AUTOSAR XML (schema 00047)
package /AUTOSAR/StdTypes
  11 x std cpp implementation data type, all with category=VALUE:
    bool
    float
    double
    int8_t: type-emitter=cstdint
    int16_t: type-emitter=cstdint
    int32_t: type-emitter=cstdint
    int64_t: type-emitter=cstdint
    uint8_t: type-emitter=cstdint
    uint16_t: type-emitter=cstdint
    uint32_t: type-emitter=cstdint
    uint64_t: type-emitter=cstdint
package /turtlesim/Application_design
  startup config set StartupConfigSet
    4 x startup config, all with startup-option{option-argument=./etc/application.json, option-kind=COMMAND-LINE-SHORT-FORM, option-name=c}:
      roslocatorStartupConfig: scheduling-policy=SCHEDULING-POLICY-ROUND-ROBIN, scheduling-priority=10
      apcontrollerStartupConfig: scheduling-policy=SCHEDULING-POLICY-FIFO, scheduling-priority=1
      apconverterStartupConfig: scheduling-policy=SCHEDULING-POLICY-ROUND-ROBIN, scheduling-priority=5
      apactuatorStartupConfig: scheduling-policy=SCHEDULING-POLICY-ROUND-ROBIN, scheduling-priority=1
package /turtlesim/Application_design/AP_controller_app
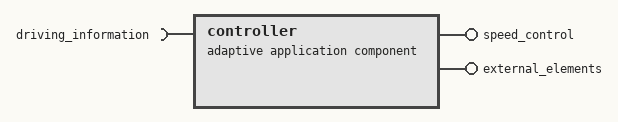
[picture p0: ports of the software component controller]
  adaptive application sw component type controller
    provide port speed_control: provided-interface=speed_control
    require port driving_information: required-interface=driving_information
    provide port external_elements: provided-interface=external_elements
  executable AP_controller: category=APPLICATION_LEVEL, build-type=BUILD-TYPE-DEBUG
    root sw component prototype controller: application-type=controller
package /turtlesim/Application_design/AP_actuator_app
  executable AP_actuator: category=APPLICATION_LEVEL, build-type=BUILD-TYPE-DEBUG
    root sw component prototype actuator: application-type=actuator
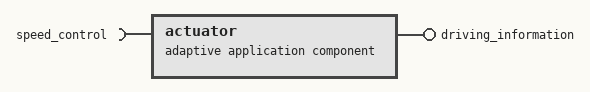
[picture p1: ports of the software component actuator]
  adaptive application sw component type actuator
    require port speed_control: required-interface=speed_control
    provide port driving_information: provided-interface=driving_information
package /turtlesim/Application_design/rosap_exe
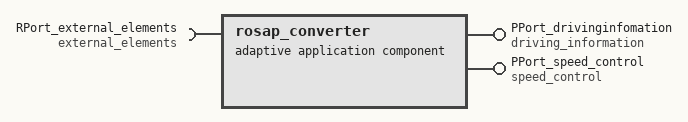
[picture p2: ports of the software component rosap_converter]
  adaptive application sw component type rosap_converter
    provide port PPort_drivinginfomation: provided-interface=driving_information
    require port RPort_external_elements: required-interface=external_elements
    provide port PPort_speed_control: provided-interface=speed_control
  executable rosap_exe
    root sw component prototype cswc: application-type=rosap_converter
package /turtlesim/Machines
  machine design PCMachineDesign: service-discover-configs=someip-service-discovery={multicast-sd-ip-address=eth0Chnl/Multicast_sdaddr, someip-service-discovery-port=12330}
    ethernet communication connector Networkendpoint: unicast-network-endpoint=eth0Chnl/Networkendpoint
  machine design raspiMachineDesign: service-discover-configs=someip-service-discovery={multicast-sd-ip-address=eth0Chnl/Multicast_sdaddr, someip-service-discovery-port=12330}
    ethernet communication connector Networkendpointraspi: unicast-network-endpoint=Networkendpointraspi
  machine design xilinxMachineDesign: service-discover-configs=someip-service-discovery={multicast-sd-ip-address=eth1Chnl/Multicast_sdaddr, someip-service-discovery-port=12330}
    ethernet communication connector Networkendpoint: unicast-network-endpoint=eth1Chnl/Networkendpoint
  ethernet cluster eth0
    ethernet physical channel eth0Chnl
      network endpoint Networkendpoint: network-endpoint-addresses=ipv-4-configuration=ipv-4-address=192.168.1.50
      network endpoint Multicast_sdaddr: network-endpoint-addresses=ipv-4-configuration=ipv-4-address=239.255.255.255
  ethernet cluster eth1
    ethernet physical channel eth1Chnl
      network endpoint Networkendpoint: network-endpoint-addresses=ipv-4-configuration=ipv-4-address=192.168.1.60
      network endpoint Multicast_sdaddr: network-endpoint-addresses=ipv-4-configuration=ipv-4-address=239.255.255.255
  ethernet cluster eth2
    ethernet physical channel eth0Chnl
      network endpoint Networkendpointraspi: network-endpoint-addresses=ipv-4-configuration=ipv-4-address=192.168.1.70
      network endpoint Multicast_sdaddr: network-endpoint-addresses=ipv-4-configuration=ipv-4-address=239.255.255.255
package /turtlesim/Machines/EM_states
  mode declaration group RaspiMachineMachineState: initial-mode=RaspiMachineMachineState/Off
    5 x mode:
      Off: value=4
      Startup: value=0
      Shutdown: value=2
      Restart: value=3
      Running: value=1
  mode declaration group PCMachineMachineState: initial-mode=PCMachineMachineState/Running
    5 x mode:
      Running: value=0
      Startup: value=1
      Shutdown: value=2
      Restart: value=3
      Off: value=4
package /turtlesim/Machines/PCMachine
  machine PCMachine: machine-design=PCMachineDesign
    function-groups:
      mode declaration group prototype MachineState: type=PCMachineMachineState
    os module instantiation Os
      resource group ControlGroup: cpu-usage=50, mem-usage=1024
    processor Processor
      4 x processor core:
        ProcessorCore{0..3}: core-id={0..3}
package /turtlesim/Machines/Raspi_Machine
  machine RaspiMachine: machine-design=PCMachineDesign
    function-groups:
      mode declaration group prototype MachineState: type=RaspiMachineMachineState
    os module instantiation Os
      resource group ControlGroup: cpu-usage=50, mem-usage=4096
    processor Processor
      4 x processor core:
        ProcessorCore{0..3}
package /turtlesim/ServiceDesign/speed_control
  service interface speed_control
    namespaces:
      symbol props apns
    events:
      data LKA_speed: type=speedtype
      data ToGoal_speed: type=speedtype
package /turtlesim/ServiceDesign/datatype
  5 x std cpp implementation data type, all with type-emitter=TYPE_EMITTER_ARA:
    speedtype: category=STRUCTURE
      namespaces:
        symbol props apns
      cpp implementation data type element l_vel: type-reference=l_vel
      cpp implementation data type element a_vel: type-reference=a_vel
    a_vel: type-reference=double
      namespaces:
        symbol props apns
    l_vel: type-reference=double
      namespaces:
        symbol props apns
    locationtype: category=STRUCTURE
      namespaces:
        symbol props apns
      cpp implementation data type element x: type-reference=double
      cpp implementation data type element y: type-reference=double
      cpp implementation data type element theta: type-reference=double
    lanetype: category=STRUCTURE
      namespaces:
        symbol props apns
      cpp implementation data type element k: type-reference=double
      cpp implementation data type element b: type-reference=double
package /turtlesim/ServiceDesign/driving_information
  service interface driving_information
    namespaces:
      symbol props ns0: symbol=apns
    events:
      data vehicle_speed: type=speedtype
      data vehicle_position: type=locationtype
package /turtlesim/ServiceDesign/external_elements
  service interface external_elements
    namespaces:
      symbol props apns
    field lane: type=lanetype, has-getter=true, has-notifier=true, has-setter=true
    field object: type=locationtype, has-getter=true, has-notifier=true, has-setter=true
package /turtlesim/deployment
  process ap_actuatorProcess: executable=AP_actuator, state-dependent-startup-config{function-group-state=MachineState.Running, startup-config=apactuatorStartupConfig}
    process state machine ModeDeclarationGroupPrototype: type=ProcessStates
  process AP_controllerProcess: executable=AP_controller, state-dependent-startup-config{function-group-state=MachineState.Running, startup-config=apcontrollerStartupConfig}
    process state machine ModeDeclarationGroupPrototype: type=ProcessStates
package /turtlesim/deployment/Mapping
  service instance to port prototype mapping PortMappingRequiredSomeipLKA: port-prototype=actuator.speed_control, process=ap_actuatorProcess, service-instance=RequiredSomeipLKA
  someip service instance to machine mapping MachineMappingRequiredSomeipLKA: communication-connector=PCMachineDesign/Networkendpoint, service-instance=RequiredSomeipLKA, udp-port=40000
  service instance to port prototype mapping PortMappingProvidedSomeipLKA: port-prototype=controller.speed_control, process=AP_controllerProcess, service-instance=ProvidedSomeipLKA
  someip service instance to machine mapping MachineMappingProvidedSomeipLKA: communication-connector=Networkendpointraspi, service-instance=ProvidedSomeipLKA, udp-port=40001
  process to machine mapping set ProcessToMachineMappingSet
    4 x process to machine mapping:
      actuatorToMachineMapping: machine=PCMachine, process=ap_actuatorProcess, shall-run-on=Processor/ProcessorCore0
      rslocatorToMachineMapping: machine=PCMachine, process=ros_locatior, shall-not-run-on=Processor/ProcessorCore0
      convverterToMachineMapping: machine=PCMachine, process=rosap_exeProcess, shall-not-run-on=Processor/ProcessorCore0
      apcontrollerToMachineMapping: machine=RaspiMachine, process=AP_controllerProcess, shall-run-on=Processor/ProcessorCore0
  service instance to port prototype mapping PortMappingProvidedSomeipSpeedControl: port-prototype=cswc.PPort_speed_control, process=rosap_exeProcess, service-instance=ProvidedSomeipSpeedControl
  service instance to port prototype mapping PortMappingProvidedSomeipdriving_information: port-prototype=actuator.driving_information, process=ap_actuatorProcess, service-instance=ProvidedSomeipdriving_information
package /turtlesim/Someip
  someip service interface deployment SomeipSpeedControl: service-interface=speed_control, service-interface-id=1401, service-interface-version={major-version=1, minor-version=0}
    someip event deployment someip_lka_speed: event=LKA_speed, event-id=45677, transport-protocol=UDP
    someip event deployment Someip_ToGoal_speed: event=ToGoal_speed, event-id=45678, transport-protocol=UDP
    someip event group SomeipEventGroup: event-group-id=1, event=[someip_lka_speed, Someip_ToGoal_speed]
  someip sd client event group timing config SomeipSdClientEventGroupTimingConfig: request-response-delay={max-value=0, min-value=0}, time-to-live=5
  someip service interface deployment Someipdriving_information: service-interface=driving_information, service-interface-id=1402, service-interface-version={major-version=1, minor-version=0}
    someip event deployment vehicle_speed: event=vehicle_speed, event-id=32769, transport-protocol=UDP
    someip event deployment vehicle_position: event=vehicle_position, event-id=32770, transport-protocol=UDP
    someip event group SomeipEventGroup: event-group-id=1, event=[vehicle_speed, vehicle_position]
package /turtlesim/Someip/Provided
  provided someip service instance ProvidedSomeipLKA: service-interface=SomeipSpeedControl, sd-server-config=SomeipSdServerServiceInstanceConfigLKA, service-instance-id=1
    someip provided event group SomeipEventGroup: event-group=SomeipSpeedControl/SomeipEventGroup, multicast-threshold=0
  someip sd server service instance config SomeipSdServerServiceInstanceConfigLKA: initial-offer-behavior={initial-delay-max-value=0.1, initial-delay-min-value=0.01, initial-repetitions-base-delay=0.2, initial-repetitions-max=10}, offer-cyclic-delay=4, request-response-delay={max-value=1.5, min-value=1.5}, service-offer-time-to-live=3
  provided someip service instance ProvidedSomeipdriving_information: service-interface=Someipdriving_information, sd-server-config=SomeipSdServerServiceInstanceConfigdriving_information, service-instance-id=3
    someip provided event group SomeipEventGroup: event-group=Someipdriving_information/SomeipEventGroup, multicast-threshold=0
  someip sd server service instance config SomeipSdServerServiceInstanceConfigdriving_information: initial-offer-behavior={initial-delay-max-value=0.1, initial-delay-min-value=0.01, initial-repetitions-base-delay=0.2, initial-repetitions-max=10}, offer-cyclic-delay=4, request-response-delay={max-value=1.5, min-value=1.5}, service-offer-time-to-live=3
package /turtlesim/Someip/Required
  required someip service instance RequiredSomeipLKA: service-interface=SomeipSpeedControl, required-minor-version=ANY, required-service-instance-id=1, sd-client-config=SomeipSdClientServiceInstanceConfigLKA
    someip required event group SomeipEventGroup: event-group=SomeipSpeedControl/SomeipEventGroup, sd-client-event-group-timing-config=SomeipSdClientEventGroupTimingConfig
  someip sd client service instance config SomeipSdClientServiceInstanceConfigLKA: initial-find-behavior={initial-delay-max-value=0.1, initial-delay-min-value=0.01, initial-repetitions-base-delay=0.2, initial-repetitions-max=3}, service-find-time-to-live=3
